AUTOSAR XML (schema 4-2-2)
package /Components
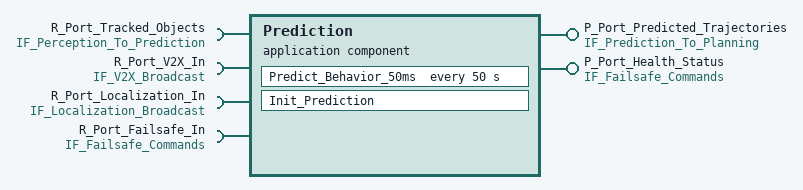
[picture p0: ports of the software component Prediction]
  application sw component type Prediction
    provide port P_Port_Predicted_Trajectories: provided-interface=IF_Prediction_To_Planning
    provide port P_Port_Health_Status: provided-interface=IF_Failsafe_Commands
    4 x require port:
      R_Port_Tracked_Objects: required-interface=IF_Perception_To_Prediction
      R_Port_V2X_In: required-interface=IF_V2X_Broadcast
      R_Port_Localization_In: required-interface=IF_Localization_Broadcast
      R_Port_Failsafe_In: required-interface=IF_Failsafe_Commands
    behavior Prediction_InternalBehavior
      init event Prediction_Init: start-on-event=Init_Prediction
      timing event Prediction_50ms: start-on-event=Predict_Behavior_50ms, period=50
      runnable Init_Prediction
        data-receive-point-by-arguments:
          access Read_Init_Localization_Status: accessed-variable={autosar-variable-in-impl-datatype={port-prototype=R_Port_Localization_In, target-data-prototype=Localization_Status_Buffer}, autosar-variable=R_Port_Localization_In.Localization_Status}
        data-send-points:
          access Send_Init_Health_Status: accessed-variable={autosar-variable-in-impl-datatype={port-prototype=P_Port_Health_Status, target-data-prototype=Health_Status_Signal}, autosar-variable=P_Port_Health_Status.Failsafe_Status}
        data-write-access:
          access Write_Init_Internal_State: accessed-variable={autosar-variable-in-impl-datatype={port-prototype=R_Port_Tracked_Objects, target-data-prototype=Prediction_Internal_State_Init}, autosar-variable=R_Port_Tracked_Objects.Tracked_Objects}
        parameter access InitParamAccess_Prediction_Model_Config: accessed-parameter=R_Port_Localization_In.Localization_Status
      runnable Predict_Behavior_50ms: minimum-start-interval=50
        data-receive-point-by-arguments:
          8 x access:
            Read_Tracked_Objects: accessed-variable={autosar-variable-in-impl-datatype={port-prototype=R_Port_Tracked_Objects, target-data-prototype=Tracked_Objects_Buffer}, autosar-variable=R_Port_Tracked_Objects.Tracked_Objects}
            Read_V2X_BSM: accessed-variable={autosar-variable-in-impl-datatype={port-prototype=R_Port_V2X_In, target-data-prototype=V2X_BSM_Queue}, autosar-variable=R_Port_V2X_In.BSM}
            Read_V2X_SPAT: accessed-variable={autosar-variable-in-impl-datatype={port-prototype=R_Port_V2X_In, target-data-prototype=V2X_SPAT_Queue}, autosar-variable=R_Port_V2X_In.SPaT}
            Read_V2X_MAP: accessed-variable={autosar-variable-in-impl-datatype={port-prototype=R_Port_V2X_In, target-data-prototype=V2X_MAP_Queue}, autosar-variable=R_Port_V2X_In.MAP}
            Read_V2X_RSI: accessed-variable={autosar-variable-in-impl-datatype={port-prototype=R_Port_V2X_In, target-data-prototype=V2X_RSI_Queue}, autosar-variable=R_Port_V2X_In.RSI}
            Read_Ego_Pose: accessed-variable={autosar-variable-in-impl-datatype={port-prototype=R_Port_Localization_In, target-data-prototype=Ego_Pose_Buffer}, autosar-variable=R_Port_Localization_In.Ego_Pose}
            Read_MRC_Command: accessed-variable={autosar-variable-in-impl-datatype={port-prototype=R_Port_Failsafe_In, target-data-prototype=MRC_Command_Latch}, autosar-variable=R_Port_Failsafe_In.MRC_Command}
            Read_SOS_Command: accessed-variable={autosar-variable-in-impl-datatype={port-prototype=R_Port_Failsafe_In, target-data-prototype=SOS_Command_Latch}, autosar-variable=R_Port_Failsafe_In.SOS_Command}
        data-send-points:
          access Send_Predicted_Trajectories: accessed-variable={autosar-variable-in-impl-datatype={port-prototype=P_Port_Predicted_Trajectories, target-data-prototype=Predicted_Trajectories_Frame}, autosar-variable=P_Port_Predicted_Trajectories.Predicted_Trajectories}
          access Send_Health_Status: accessed-variable={autosar-variable-in-impl-datatype={port-prototype=P_Port_Health_Status, target-data-prototype=Health_Status_Signal}, autosar-variable=P_Port_Health_Status.Failsafe_Status}
        data-write-access:
          access Write_Prediction_Internal_State: accessed-variable={autosar-variable-in-impl-datatype={port-prototype=P_Port_Predicted_Trajectories, target-data-prototype=Prediction_Internal_State}, autosar-variable=P_Port_Predicted_Trajectories.Predicted_Trajectories}
        parameter access RuntimeParamAccess_Failsafe_Status: accessed-parameter=R_Port_Failsafe_In.Failsafe_Status
